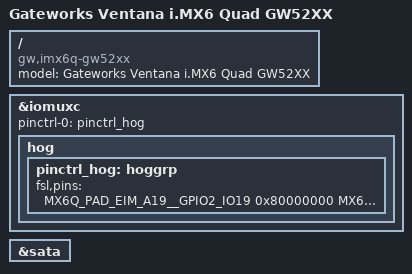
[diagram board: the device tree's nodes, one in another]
/*
 * Copyright 2013 Gateworks Corporation
 *
 * The code contained herein is licensed under the GNU General Public
 * License. You may obtain a copy of the GNU General Public License
 * Version 2 or later at the following locations:
 *
 * http://www.opensource.org/licenses/gpl-license.html
 * http://www.gnu.org/copyleft/gpl.html
 */

/dts-v1/;
#include "imx6q.dtsi"
#include "imx6qdl-gw52xx.dtsi"

/ {
	model = "Gateworks Ventana i.MX6 Quad GW52XX";
	compatible = "gw,imx6q-gw52xx", "gw,ventana", "fsl,imx6q";
};

&iomuxc {
	pinctrl-names = "default";
	pinctrl-0 = <&pinctrl_hog>;

	hog {
		pinctrl_hog: hoggrp {
			fsl,pins = <
				MX6Q_PAD_EIM_A19__GPIO2_IO19   0x80000000 /* MEZZ_DIO0 */
				MX6Q_PAD_EIM_A20__GPIO2_IO18   0x80000000 /* MEZZ_DIO1 */
				MX6Q_PAD_EIM_D22__GPIO3_IO22   0x80000000 /* OTG_PWR_EN */
				MX6Q_PAD_EIM_D31__GPIO3_IO31   0x80000000 /* VIDDEC_PDN# */
				MX6Q_PAD_ENET_TXD0__GPIO1_IO30 0x80000000 /* PHY Reset */
				MX6Q_PAD_ENET_TXD1__GPIO1_IO29 0x80000000 /* PCIE_RST# */
				MX6Q_PAD_ENET_RXD0__GPIO1_IO27 0x80000000 /* GPS_PWDN */
				MX6Q_PAD_ENET_RXD1__GPIO1_IO26 0x80000000 /* GPS_PPS */
				MX6Q_PAD_GPIO_0__CCM_CLKO1     0x000130b0 /* AUD4_MCK */
				MX6Q_PAD_GPIO_2__GPIO1_IO02    0x80000000 /* USB_SEL_PCI */
				MX6Q_PAD_GPIO_17__GPIO7_IO12   0x80000000 /* TOUCH_IRQ# */
				MX6Q_PAD_KEY_COL0__GPIO4_IO06  0x80000000 /* user1 led */
				MX6Q_PAD_KEY_ROW0__GPIO4_IO07  0x80000000 /* user2 led */
				MX6Q_PAD_KEY_ROW4__GPIO4_IO15  0x80000000 /* user3 led */
				MX6Q_PAD_SD2_CMD__GPIO1_IO11   0x80000000 /* LVDS_TCH# */
				MX6Q_PAD_SD3_DAT5__GPIO7_IO00  0x80000000 /* SD3_CD# */
				MX6Q_PAD_SD4_DAT3__GPIO2_IO11  0x80000000 /* UART2_EN# */
			 >;
		};
	};
};

&sata {
        status = "okay";
};
